AUTOSAR XML (schema 00044)
package /E40_Platform_System_SystemPackage/Components
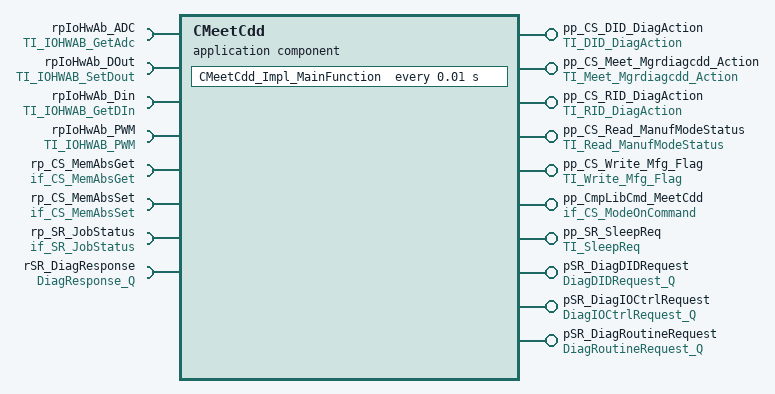
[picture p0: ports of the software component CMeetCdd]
  application sw component type CMeetCdd
    7 x provide port:
      pp_CS_DID_DiagAction: server-com-spec{operation=DID_DiagAction, queue-length=1}, provided-interface=TI_DID_DiagAction
      pp_CS_Meet_Mgrdiagcdd_Action: server-com-spec{operation=Meet_Mgrdiagcdd_Action, queue-length=1}, provided-interface=TI_Meet_Mgrdiagcdd_Action
      pp_CS_RID_DiagAction: server-com-spec{operation=RID_DiagAction, queue-length=1}, provided-interface=TI_RID_DiagAction
      pp_CS_Read_ManufModeStatus: server-com-spec{operation=Read_ManufModeStatus, queue-length=1}, provided-interface=TI_Read_ManufModeStatus
      pp_CS_Write_Mfg_Flag: server-com-spec{operation=Write_Mfg_Flag, queue-length=1}, provided-interface=TI_Write_Mfg_Flag
      pp_CmpLibCmd_MeetCdd: server-com-spec{operation=Impl_OnCommand, queue-length=1}, provided-interface=if_CS_ModeOnCommand
      pp_SR_SleepReq: nonqueued-sender-com-spec{data-element=SleepReqData, init-value=constant-reference=CMeetCddSleepReqDataValue0}, provided-interface=TI_SleepReq
    7 x require port:
      rpIoHwAb_ADC: required-com-specs=[GetAsyncRawAdc, GetProcessedAdc, GetSyncRawAdc], required-interface=TI_IOHWAB_GetAdc
      rpIoHwAb_DOut: required-com-specs=[SetOutputGroup, SetOutputPin], required-interface=TI_IOHWAB_SetDout
      rpIoHwAb_Din: required-com-specs=[GetAsyncRawInput, GetInputGroup, GetProcessedInput, GetSyncRawInput], required-interface=TI_IOHWAB_GetDIn
      rpIoHwAb_PWM: required-com-specs=[PwmSetDuty, PwmSetDutyAndPeriod, PwmSetIdeal], required-interface=TI_IOHWAB_PWM
      rp_CS_MemAbsGet: required-interface=if_CS_MemAbsGet
        required-com-specs:
          Get_BsConst_Audio_Element
          Get_BsConst_Communication_Element
          Get_BsConst_EngOffTimer_Element
          Get_BsConst_FuelGauge_Element
          Get_BsConst_OilGauge_Element
          Get_BsConst_PowerGauge_Element
          Get_BsConst_Power_Element
          Get_BsConst_RealTimeClock_Element
          Get_BsConst_ServiceReminder_Element
          Get_BsConst_SpeedoGauge_Element
          Get_BsConst_TachoGauge_Element
          Get_BsConst_TempGauge_Element
          Get_BsConst_TripComputer_Element
          Get_BsConst_Warning_Element
          Get_BsCys_Certicificate_Element
          Get_BsDiag_Dtc_Element
          Get_BsDiag_ErrorRecord_Element
          Get_BsReten_Audio_Element
          Get_BsReten_Communication_Element
          Get_BsReten_Display_Element
          Get_BsReten_Gauges_Element
          Get_BsReten_Illumination_Element
          Get_BsReten_Odometer_Element
          Get_BsReten_Personalization_Element
          Get_BsReten_Power_Element
          Get_BsReten_RealTimeClock_Element
          Get_BsReten_Tripcomputer_Element
          Get_BsReten_Warning_Element
          Get_BsRt_CusDlt_Element
          Get_BsRt_FuelGauge_Element
          Get_BsRt_Illumination_Element
          Get_BsRt_Odometer_Element
          Get_BsRt_OilGauge_Element
          Get_BsRt_Personalization_Element
          Get_BsRt_PowerGauge_Element
          Get_BsRt_RealTimeClock_Element
          Get_BsRt_SpeedoGauge_Element
          Get_BsRt_TachoGauge_Element
          Get_BsRt_TempGauge_Element
          Get_BsRt_TripComputer_Element
          Get_BsRt_Warning_Element
          Get_BsShare_EcuPartNumber_Element
          Get_BsShare_SwUpdFotaFinPrint_Element
          Get_BsShare_SwUpdFotaMode_Element
          Get_BsShare_SwUpdFotaStatus_Element
          Get_BsShare_SwUpdFotadecrypt_Element
          Get_BsShare_SwUpdReflash_Element
          Get_BsShare_VehicleConfig_Element
          Get_BsShare_VisMeet_Element
          Get_RefCys_Certicificate1_Element
          Get_RefCys_Certicificate_Element
          Get_BsShare_VisteonPartNumber
          Get_BsShare_VisteonPCBPartNumber
          Get_BsShare_SMTPlantNumber
          Get_BsShare_SMTManufacturingDate
          Get_BsShare_ProductSerialNumber
          Get_BsShare_PCBSerialNumber
          Get_BsShare_HWModification
          Get_BsShare_AssemblyPlantNumber
          Get_BsShare_AssemblyManufacturingDate
          Get_BsShare_VisMeet_EOLEntry_Element
          Get_BsConst_Temperature_Sensor_Conv_SafeCopy2
          Get_BsConst_Temperature_Sensor_Conv_SafeCopy1
          Get_BsConst_Temperature_Sensor_Conv
          Get_BsConst_Temp_Threshold_Hysteresis_Derating_SafeCopy2
          Get_BsConst_Temp_Threshold_Hysteresis_Derating_SafeCopy1
          Get_BsConst_Temp_Threshold_Hysteresis_Derating
          Get_BsConst_PWM_boost_bypass_duty_SafeCopy2
          Get_BsConst_PWM_boost_bypass_duty_SafeCopy1
          Get_BsConst_PWM_boost_bypass_duty
          Get_BsConst_PCB_Temperature_Sensor_Conv_SafeCopy2
          Get_BsConst_PCB_Temperature_Sensor_Conv_SafeCopy1
          Get_BsConst_PCB_Temperature_Sensor_Conv
          Get_BsConst_Lookup_Curve_HotSpot_Coef_Y_SafeCopy2
          Get_BsConst_Lookup_Curve_HotSpot_Coef_Y_SafeCopy1
          Get_BsConst_Lookup_Curve_HotSpot_Coef_Y
          Get_BsConst_Lookup_Curve_HotSpot_Coef_X_SafeCopy2
          Get_BsConst_Lookup_Curve_HotSpot_Coef_X_SafeCopy1
          Get_BsConst_Lookup_Curve_HotSpot_Coef_X
          Get_BsConst_Display_Illum_Max_Level_SafeCopy2
          Get_BsConst_Display_Illum_Max_Level_SafeCopy1
          Get_BsConst_Display_Illum_Max_Level
          Get_BsConst_Derating_Backlight_Disable_SafeCopy2
          Get_BsConst_Derating_Backlight_Disable_SafeCopy1
          Get_BsConst_Derating_Backlight_Disable
          Get_BsConst_Compensation_Line_Slope_m_SafeCopy2
          Get_BsConst_Compensation_Line_Slope_m_SafeCopy1
          Get_BsConst_Compensation_Line_Slope_m
          Get_BsConst_Compensation_Line_Shift_b_SafeCopy2
          Get_BsConst_Compensation_Line_Shift_b_SafeCopy1
          Get_BsConst_Compensation_Line_Shift_b
          Get_BsConst_BsConst_Illumination_ReservedByte_SafeCopy2
          Get_BsConst_BsConst_Illumination_ReservedByte_SafeCopy1
          Get_BsConst_BsConst_Illumination_ReservedByte
      rp_CS_MemAbsSet: required-interface=if_CS_MemAbsSet
        required-com-specs:
          Set_BsConst_Audio_Element
          Set_BsConst_Communication_Element
          Set_BsConst_EngOffTimer_Element
          Set_BsConst_FuelGauge_Element
          Set_BsConst_OilGauge_Element
          Set_BsConst_PowerGauge_Element
          Set_BsConst_Power_Element
          Set_BsConst_RealTimeClock_Element
          Set_BsConst_ServiceReminder_Element
          Set_BsConst_SpeedoGauge_Element
          Set_BsConst_TachoGauge_Element
          Set_BsConst_TempGauge_Element
          Set_BsConst_TripComputer_Element
          Set_BsConst_Warning_Element
          Set_BsCys_Certicificate_Element
          Set_BsDiag_Dtc_Element
          Set_BsDiag_ErrorRecord_Element
          Set_BsReten_Audio_Element
          Set_BsReten_Communication_Element
          Set_BsReten_Display_Element
          Set_BsReten_Gauges_Element
          Set_BsReten_Illumination_Element
          Set_BsReten_Odometer_Element
          Set_BsReten_Personalization_Element
          Set_BsReten_Power_Element
          Set_BsReten_RealTimeClock_Element
          Set_BsReten_Tripcomputer_Element
          Set_BsReten_Warning_Element
          Set_BsRt_CusDlt_Element
          Set_BsRt_FuelGauge_Element
          Set_BsRt_Illumination_Element
          Set_BsRt_Odometer_Element
          Set_BsRt_OilGauge_Element
          Set_BsRt_Personalization_Element
          Set_BsRt_PowerGauge_Element
          Set_BsRt_RealTimeClock_Element
          Set_BsRt_SpeedoGauge_Element
          Set_BsRt_TachoGauge_Element
          Set_BsRt_TempGauge_Element
          Set_BsRt_TripComputer_Element
          Set_BsRt_Warning_Element
          Set_BsShare_EcuPartNumber_Element
          Set_BsShare_SwUpdFotaFinPrint_Element
          Set_BsShare_SwUpdFotaMode_Element
          Set_BsShare_SwUpdFotaStatus_Element
          Set_BsShare_SwUpdFotadecrypt_Element
          Set_BsShare_SwUpdReflash_Element
          Set_BsShare_VehicleConfig_Element
          Set_BsShare_VisMeet_Element
          Set_RefCys_Certicificate1_Element
          Set_RefCys_Certicificate_Element
          Set_BsShare_VisteonPartNumber
          Set_BsShare_VisteonPCBPartNumber
          Set_BsShare_SMTPlantNumber
          Set_BsShare_SMTManufacturingDate
          Set_BsShare_ProductSerialNumber
          Set_BsShare_PCBSerialNumber
          Set_BsShare_HWModification
          Set_BsShare_AssemblyPlantNumber
          Set_BsShare_AssemblyManufacturingDate
          Set_BsShare_VisMeet_EOLEntry_Element
          Set_BsConst_Temperature_Sensor_Conv_SafeCopy2
          Set_BsConst_Temperature_Sensor_Conv_SafeCopy1
          Set_BsConst_Temperature_Sensor_Conv
          Set_BsConst_Temp_Threshold_Hysteresis_Derating_SafeCopy2
          Set_BsConst_Temp_Threshold_Hysteresis_Derating_SafeCopy1
          Set_BsConst_Temp_Threshold_Hysteresis_Derating
          Set_BsConst_PWM_boost_bypass_duty_SafeCopy2
          Set_BsConst_PWM_boost_bypass_duty_SafeCopy1
          Set_BsConst_PWM_boost_bypass_duty
          Set_BsConst_PCB_Temperature_Sensor_Conv_SafeCopy2
          Set_BsConst_PCB_Temperature_Sensor_Conv_SafeCopy1
          Set_BsConst_PCB_Temperature_Sensor_Conv
          Set_BsConst_Lookup_Curve_HotSpot_Coef_Y_SafeCopy2
          Set_BsConst_Lookup_Curve_HotSpot_Coef_Y_SafeCopy1
          Set_BsConst_Lookup_Curve_HotSpot_Coef_Y
          Set_BsConst_Lookup_Curve_HotSpot_Coef_X_SafeCopy2
          Set_BsConst_Lookup_Curve_HotSpot_Coef_X_SafeCopy1
          Set_BsConst_Lookup_Curve_HotSpot_Coef_X
          Set_BsConst_Display_Illum_Max_Level_SafeCopy2
          Set_BsConst_Display_Illum_Max_Level_SafeCopy1
          Set_BsConst_Display_Illum_Max_Level
          Set_BsConst_Derating_Backlight_Disable_SafeCopy2
          Set_BsConst_Derating_Backlight_Disable_SafeCopy1
          Set_BsConst_Derating_Backlight_Disable
          Set_BsConst_Compensation_Line_Slope_m_SafeCopy2
          Set_BsConst_Compensation_Line_Slope_m_SafeCopy1
          Set_BsConst_Compensation_Line_Slope_m
          Set_BsConst_Compensation_Line_Shift_b_SafeCopy2
          Set_BsConst_Compensation_Line_Shift_b_SafeCopy1
          Set_BsConst_Compensation_Line_Shift_b
          Set_BsConst_BsConst_Illumination_ReservedByte_SafeCopy2
          Set_BsConst_BsConst_Illumination_ReservedByte_SafeCopy1
          Set_BsConst_BsConst_Illumination_ReservedByte
      rp_SR_JobStatus: required-interface=if_SR_JobStatus
        required-com-specs:
          data-element=JobStatus_BsConst_Audio_Element, init-value=constant-reference=CMeetCddJobStatus_BsConst_Audio_ElementValue0
          data-element=JobStatus_BsConst_Communication_Element, init-value=constant-reference=CMeetCddJobStatus_BsConst_Communication_ElementValue0
          data-element=JobStatus_BsConst_EngOffTimer_Element, init-value=constant-reference=CMeetCddJobStatus_BsConst_EngOffTimer_ElementValue0
          data-element=JobStatus_BsConst_FuelGauge_Element, init-value=constant-reference=CMeetCddJobStatus_BsConst_FuelGauge_ElementValue0
          data-element=JobStatus_BsConst_OilGauge_Element, init-value=constant-reference=CMeetCddJobStatus_BsConst_OilGauge_ElementValue0
          data-element=JobStatus_BsConst_PowerGauge_Element, init-value=constant-reference=CMeetCddJobStatus_BsConst_PowerGauge_ElementValue0
          data-element=JobStatus_BsConst_Power_Element, init-value=constant-reference=CMeetCddJobStatus_BsConst_Power_ElementValue0
          data-element=JobStatus_BsConst_RealTimeClock_Element, init-value=constant-reference=CMeetCddJobStatus_BsConst_RealTimeClock_ElementValue0
          data-element=JobStatus_BsConst_ServiceReminder_Element, init-value=constant-reference=CMeetCddJobStatus_BsConst_ServiceReminder_ElementValue0
          data-element=JobStatus_BsConst_SpeedoGauge_Element, init-value=constant-reference=CMeetCddJobStatus_BsConst_SpeedoGauge_ElementValue0
          data-element=JobStatus_BsConst_TachoGauge_Element, init-value=constant-reference=CMeetCddJobStatus_BsConst_TachoGauge_ElementValue0
          data-element=JobStatus_BsConst_TempGauge_Element, init-value=constant-reference=CMeetCddJobStatus_BsConst_TempGauge_ElementValue0
          data-element=JobStatus_BsConst_TripComputer_Element, init-value=constant-reference=CMeetCddJobStatus_BsConst_TripComputer_ElementValue0
          data-element=JobStatus_BsConst_Warning_Element, init-value=constant-reference=CMeetCddJobStatus_BsConst_Warning_ElementValue0
          data-element=JobStatus_BsCys_Certicificate_Element, init-value=constant-reference=CMeetCddJobStatus_BsCys_Certicificate_ElementValue0
          data-element=JobStatus_BsDiag_Dtc_Element, init-value=constant-reference=CMeetCddJobStatus_BsDiag_Dtc_ElementValue0
          data-element=JobStatus_BsDiag_ErrorRecord_Element, init-value=constant-reference=CMeetCddJobStatus_BsDiag_ErrorRecord_ElementValue0
          data-element=JobStatus_BsReten_Audio_Element, init-value=constant-reference=CMeetCddJobStatus_BsReten_Audio_ElementValue0
          data-element=JobStatus_BsReten_Communication_Element, init-value=constant-reference=CMeetCddJobStatus_BsReten_Communication_ElementValue0
          data-element=JobStatus_BsReten_Display_Element, init-value=constant-reference=CMeetCddJobStatus_BsReten_Display_ElementValue0
          data-element=JobStatus_BsReten_Gauges_Element, init-value=constant-reference=CMeetCddJobStatus_BsReten_Gauges_ElementValue0
          data-element=JobStatus_BsReten_Illumination_Element, init-value=constant-reference=CMeetCddJobStatus_BsReten_Illumination_ElementValue0
          data-element=JobStatus_BsReten_Odometer_Element, init-value=constant-reference=CMeetCddJobStatus_BsReten_Odometer_ElementValue0
          data-element=JobStatus_BsReten_Personalization_Element, init-value=constant-reference=CMeetCddJobStatus_BsReten_Personalization_ElementValue0
          data-element=JobStatus_BsReten_Power_Element, init-value=constant-reference=CMeetCddJobStatus_BsReten_Power_ElementValue0
          data-element=JobStatus_BsReten_RealTimeClock_Element, init-value=constant-reference=CMeetCddJobStatus_BsReten_RealTimeClock_ElementValue0
          data-element=JobStatus_BsReten_Tripcomputer_Element, init-value=constant-reference=CMeetCddJobStatus_BsReten_Tripcomputer_ElementValue0
          data-element=JobStatus_BsReten_Warning_Element, init-value=constant-reference=CMeetCddJobStatus_BsReten_Warning_ElementValue0
          data-element=JobStatus_BsRt_CusDlt_Element, init-value=constant-reference=CMeetCddJobStatus_BsRt_CusDlt_ElementValue0
          data-element=JobStatus_BsRt_FuelGauge_Element, init-value=constant-reference=CMeetCddJobStatus_BsRt_FuelGauge_ElementValue0
          data-element=JobStatus_BsRt_Illumination_Element, init-value=constant-reference=CMeetCddJobStatus_BsRt_Illumination_ElementValue0
          data-element=JobStatus_BsRt_Odometer_Element, init-value=constant-reference=CMeetCddJobStatus_BsRt_Odometer_ElementValue0
          data-element=JobStatus_BsRt_OilGauge_Element, init-value=constant-reference=CMeetCddJobStatus_BsRt_OilGauge_ElementValue0
          data-element=JobStatus_BsRt_Personalization_Element, init-value=constant-reference=CMeetCddJobStatus_BsRt_Personalization_ElementValue0
          data-element=JobStatus_BsRt_PowerGauge_Element, init-value=constant-reference=CMeetCddJobStatus_BsRt_PowerGauge_ElementValue0
          data-element=JobStatus_BsRt_RealTimeClock_Element, init-value=constant-reference=CMeetCddJobStatus_BsRt_RealTimeClock_ElementValue0
          data-element=JobStatus_BsRt_SpeedoGauge_Element, init-value=constant-reference=CMeetCddJobStatus_BsRt_SpeedoGauge_ElementValue0
          data-element=JobStatus_BsRt_TachoGauge_Element, init-value=constant-reference=CMeetCddJobStatus_BsRt_TachoGauge_ElementValue0
          data-element=JobStatus_BsRt_TempGauge_Element, init-value=constant-reference=CMeetCddJobStatus_BsRt_TempGauge_ElementValue0
          data-element=JobStatus_BsRt_TripComputer_Element, init-value=constant-reference=CMeetCddJobStatus_BsRt_TripComputer_ElementValue0
          data-element=JobStatus_BsRt_Warning_Element, init-value=constant-reference=CMeetCddJobStatus_BsRt_Warning_ElementValue0
          data-element=JobStatus_BsShare_EcuPartNumber_Element, init-value=constant-reference=CMeetCddJobStatus_BsShare_EcuPartNumber_ElementValue0
          data-element=JobStatus_BsShare_SwUpdFotaFinPrint_Element, init-value=constant-reference=CMeetCddJobStatus_BsShare_SwUpdFotaFinPrint_ElementValue0
          data-element=JobStatus_BsShare_SwUpdFotaMode_Element, init-value=constant-reference=CMeetCddJobStatus_BsShare_SwUpdFotaMode_ElementValue0
          data-element=JobStatus_BsShare_SwUpdFotaStatus_Element, init-value=constant-reference=CMeetCddJobStatus_BsShare_SwUpdFotaStatus_ElementValue0
          data-element=JobStatus_BsShare_SwUpdFotadecrypt_Element, init-value=constant-reference=CMeetCddJobStatus_BsShare_SwUpdFotadecrypt_ElementValue0
          data-element=JobStatus_BsShare_SwUpdReflash_Element, init-value=constant-reference=CMeetCddJobStatus_BsShare_SwUpdReflash_ElementValue0
          data-element=JobStatus_BsShare_VehicleConfig_Element, init-value=constant-reference=CMeetCddJobStatus_BsShare_VehicleConfig_ElementValue0
          data-element=JobStatus_BsShare_VisMeet_Element, init-value=constant-reference=CMeetCddJobStatus_BsShare_VisMeet_ElementValue0
          data-element=JobStatus_RefCys_Certicificate1_Element, init-value=constant-reference=CMeetCddJobStatus_RefCys_Certicificate1_ElementValue0
          data-element=JobStatus_RefCys_Certicificate_Element, init-value=constant-reference=CMeetCddJobStatus_RefCys_Certicificate_ElementValue0
          data-element=JobStatus_BsShare_VisMeet_EOLEntry_Element, init-value=constant-reference=CMeetCddJobStatus_BsShare_VisMeet_EOLEntry_ElementValue0
          data-element=JobStatus_BsShare_AssemblyManufacturingDate, init-value=constant-reference=CMeetCddJobStatus_BsShare_AssemblyManufacturingDateValue0
          data-element=JobStatus_BsShare_AssemblyPlantNumber, init-value=constant-reference=CMeetCddJobStatus_BsShare_AssemblyPlantNumberValue0
          data-element=JobStatus_BsShare_HWModification, init-value=constant-reference=CMeetCddJobStatus_BsShare_HWModificationValue0
          data-element=JobStatus_BsShare_PCBSerialNumber, init-value=constant-reference=CMeetCddJobStatus_BsShare_PCBSerialNumberValue0
          data-element=JobStatus_BsShare_ProductSerialNumber, init-value=constant-reference=CMeetCddJobStatus_BsShare_ProductSerialNumberValue0
          data-element=JobStatus_BsShare_SMTManufacturingDate, init-value=constant-reference=CMeetCddJobStatus_BsShare_SMTManufacturingDateValue0
          data-element=JobStatus_BsShare_SMTPlantNumber, init-value=constant-reference=CMeetCddJobStatus_BsShare_SMTPlantNumberValue0
          data-element=JobStatus_BsShare_VisteonPCBPartNumber, init-value=constant-reference=CMeetCddJobStatus_BsShare_VisteonPCBPartNumberValue0
          data-element=JobStatus_BsShare_VisteonPartNumber, init-value=constant-reference=CMeetCddJobStatus_BsShare_VisteonPartNumberValue0
          data-element=JobStatus_BsConst_BsConst_Illumination_ReservedByte, init-value=constant-reference=CMeetCddJobStatus_BsConst_BsConst_Illumination_ReservedByteValue0
          data-element=JobStatus_BsConst_BsConst_Illumination_ReservedByte_SafeCopy1, init-value=constant-reference=CMeetCddJobStatus_BsConst_BsConst_Illumination_ReservedByte_SafeCopy1Value0
          data-element=JobStatus_BsConst_BsConst_Illumination_ReservedByte_SafeCopy2, init-value=constant-reference=CMeetCddJobStatus_BsConst_BsConst_Illumination_ReservedByte_SafeCopy2Value0
          data-element=JobStatus_BsConst_Compensation_Line_Shift_b, init-value=constant-reference=CMeetCddJobStatus_BsConst_Compensation_Line_Shift_bValue0
          data-element=JobStatus_BsConst_Compensation_Line_Shift_b_SafeCopy1, init-value=constant-reference=CMeetCddJobStatus_BsConst_Compensation_Line_Shift_b_SafeCopy1Value0
          data-element=JobStatus_BsConst_Compensation_Line_Shift_b_SafeCopy2, init-value=constant-reference=CMeetCddJobStatus_BsConst_Compensation_Line_Shift_b_SafeCopy2Value0
          data-element=JobStatus_BsConst_Compensation_Line_Slope_m, init-value=constant-reference=CMeetCddJobStatus_BsConst_Compensation_Line_Slope_mValue0
          data-element=JobStatus_BsConst_Compensation_Line_Slope_m_SafeCopy1, init-value=constant-reference=CMeetCddJobStatus_BsConst_Compensation_Line_Slope_m_SafeCopy1Value0
          data-element=JobStatus_BsConst_Compensation_Line_Slope_m_SafeCopy2, init-value=constant-reference=CMeetCddJobStatus_BsConst_Compensation_Line_Slope_m_SafeCopy2Value0
          data-element=JobStatus_BsConst_Derating_Backlight_Disable, init-value=constant-reference=CMeetCddJobStatus_BsConst_Derating_Backlight_DisableValue0
          data-element=JobStatus_BsConst_Derating_Backlight_Disable_SafeCopy1, init-value=constant-reference=CMeetCddJobStatus_BsConst_Derating_Backlight_Disable_SafeCopy1Value0
          data-element=JobStatus_BsConst_Derating_Backlight_Disable_SafeCopy2, init-value=constant-reference=CMeetCddJobStatus_BsConst_Derating_Backlight_Disable_SafeCopy2Value0
          data-element=JobStatus_BsConst_Display_Illum_Max_Level, init-value=constant-reference=CMeetCddJobStatus_BsConst_Display_Illum_Max_LevelValue0
          data-element=JobStatus_BsConst_Display_Illum_Max_Level_SafeCopy1, init-value=constant-reference=CMeetCddJobStatus_BsConst_Display_Illum_Max_Level_SafeCopy1Value0
          data-element=JobStatus_BsConst_Display_Illum_Max_Level_SafeCopy2, init-value=constant-reference=CMeetCddJobStatus_BsConst_Display_Illum_Max_Level_SafeCopy2Value0
          data-element=JobStatus_BsConst_Lookup_Curve_HotSpot_Coef_X, init-value=constant-reference=CMeetCddJobStatus_BsConst_Lookup_Curve_HotSpot_Coef_XValue0
          data-element=JobStatus_BsConst_Lookup_Curve_HotSpot_Coef_X_SafeCopy1, init-value=constant-reference=CMeetCddJobStatus_BsConst_Lookup_Curve_HotSpot_Coef_X_SafeCopy1Value0
          data-element=JobStatus_BsConst_Lookup_Curve_HotSpot_Coef_X_SafeCopy2, init-value=constant-reference=CMeetCddJobStatus_BsConst_Lookup_Curve_HotSpot_Coef_X_SafeCopy2Value0
          data-element=JobStatus_BsConst_Lookup_Curve_HotSpot_Coef_Y, init-value=constant-reference=CMeetCddJobStatus_BsConst_Lookup_Curve_HotSpot_Coef_YValue0
          data-element=JobStatus_BsConst_Lookup_Curve_HotSpot_Coef_Y_SafeCopy1, init-value=constant-reference=CMeetCddJobStatus_BsConst_Lookup_Curve_HotSpot_Coef_Y_SafeCopy1Value0
          data-element=JobStatus_BsConst_Lookup_Curve_HotSpot_Coef_Y_SafeCopy2, init-value=constant-reference=CMeetCddJobStatus_BsConst_Lookup_Curve_HotSpot_Coef_Y_SafeCopy2Value0
          data-element=JobStatus_BsConst_PCB_Temperature_Sensor_Conv, init-value=constant-reference=CMeetCddJobStatus_BsConst_PCB_Temperature_Sensor_ConvValue0
          data-element=JobStatus_BsConst_PCB_Temperature_Sensor_Conv_SafeCopy1, init-value=constant-reference=CMeetCddJobStatus_BsConst_PCB_Temperature_Sensor_Conv_SafeCopy1Value0
          data-element=JobStatus_BsConst_PCB_Temperature_Sensor_Conv_SafeCopy2, init-value=constant-reference=CMeetCddJobStatus_BsConst_PCB_Temperature_Sensor_Conv_SafeCopy2Value0
          data-element=JobStatus_BsConst_PWM_boost_bypass_duty, init-value=constant-reference=CMeetCddJobStatus_BsConst_PWM_boost_bypass_dutyValue0
          data-element=JobStatus_BsConst_PWM_boost_bypass_duty_SafeCopy1, init-value=constant-reference=CMeetCddJobStatus_BsConst_PWM_boost_bypass_duty_SafeCopy1Value0
          data-element=JobStatus_BsConst_PWM_boost_bypass_duty_SafeCopy2, init-value=constant-reference=CMeetCddJobStatus_BsConst_PWM_boost_bypass_duty_SafeCopy2Value0
          data-element=JobStatus_BsConst_Temp_Threshold_Hysteresis_Derating, init-value=constant-reference=CMeetCddJobStatus_BsConst_Temp_Threshold_Hysteresis_DeratingValue0
          data-element=JobStatus_BsConst_Temp_Threshold_Hysteresis_Derating_SafeCopy1, init-value=constant-reference=CMeetCddJobStatus_BsConst_Temp_Threshold_Hysteresis_Derating_SafeCopy1Value0
          data-element=JobStatus_BsConst_Temp_Threshold_Hysteresis_Derating_SafeCopy2, init-value=constant-reference=CMeetCddJobStatus_BsConst_Temp_Threshold_Hysteresis_Derating_SafeCopy2Value0
          data-element=JobStatus_BsConst_Temperature_Sensor_Conv, init-value=constant-reference=CMeetCddJobStatus_BsConst_Temperature_Sensor_ConvValue0
          data-element=JobStatus_BsConst_Temperature_Sensor_Conv_SafeCopy1, init-value=constant-reference=CMeetCddJobStatus_BsConst_Temperature_Sensor_Conv_SafeCopy1Value0
          data-element=JobStatus_BsConst_Temperature_Sensor_Conv_SafeCopy2, init-value=constant-reference=CMeetCddJobStatus_BsConst_Temperature_Sensor_Conv_SafeCopy2Value0
    provide port pSR_DiagDIDRequest: queued-sender-com-spec=DiagDIDRequestData, provided-interface=DiagDIDRequest_Q
    provide port pSR_DiagIOCtrlRequest: queued-sender-com-spec=DiagIOCtrlRequestData, provided-interface=DiagIOCtrlRequest_Q
    provide port pSR_DiagRoutineRequest: queued-sender-com-spec=DiagRoutineRequestData, provided-interface=DiagRoutineRequest_Q
    require port rSR_DiagResponse: queued-receiver-com-spec{data-element=DiagResponseData, queue-length=2}, required-interface=DiagResponse_Q
    behavior IB_CMeetCdd
      operation invoked event OIE_pp_CS_DID_DiagAction_CMeetCdd_DID_DiagActionTrigByDID_DiagAction: start-on-event=CMeetCdd_DID_DiagAction, operation=pp_CS_DID_DiagAction.DID_DiagAction
      timing event TECMeetCdd_Impl_MainFunction: start-on-event=CMeetCdd_Impl_MainFunction, period=0.01
      5 x operation invoked event:
        OIE_pp_CmpLibCmd_MeetCdd_CMeetCdd_Impl_OnCommandTrigByImpl_OnCommand: start-on-event=CMeetCdd_Impl_OnCommand, operation=pp_CmpLibCmd_MeetCdd.Impl_OnCommand
        OIE_pp_CS_Meet_Mgrdiagcdd_Action_CMeetCdd_Meet_Mgrdiagcdd_ActionTrigByMeet_Mgrdiagcdd_Action: start-on-event=CMeetCdd_Meet_Mgrdiagcdd_Action, operation=pp_CS_Meet_Mgrdiagcdd_Action.Meet_Mgrdiagcdd_Action
        OIE_pp_CS_RID_DiagAction_CMeetCdd_RID_DiagActionTrigByRID_DiagAction: start-on-event=CMeetCdd_RID_DiagAction, operation=pp_CS_RID_DiagAction.RID_DiagAction
        OIE_pp_CS_Read_ManufModeStatus_CMeetCdd_Read_ManufModeStatusTrigByRead_ManufModeStatus: start-on-event=CMeetCdd_Read_ManufModeStatus, operation=pp_CS_Read_ManufModeStatus.Read_ManufModeStatus
        OIE_pp_CS_Write_Mfg_Flag_CMeetCdd_Write_Mfg_FlagTrigByWrite_Mfg_Flag: start-on-event=CMeetCdd_Write_Mfg_Flag, operation=pp_CS_Write_Mfg_Flag.Write_Mfg_Flag
      port-api-options:
        enable-take-address=false, indirect-api=false, port=pp_CS_DID_DiagAction
        enable-take-address=false, indirect-api=false, port=pp_CS_Meet_Mgrdiagcdd_Action
        enable-take-address=false, indirect-api=false, port=pp_CS_RID_DiagAction
        enable-take-address=false, indirect-api=false, port=pp_CS_Read_ManufModeStatus
        enable-take-address=false, indirect-api=false, port=pp_CS_Write_Mfg_Flag
        enable-take-address=false, indirect-api=false, port=pp_CmpLibCmd_MeetCdd
        enable-take-address=false, indirect-api=false, port=pp_SR_SleepReq
        enable-take-address=false, indirect-api=false, port=rpIoHwAb_ADC
        enable-take-address=false, indirect-api=false, port=rpIoHwAb_DOut
        enable-take-address=false, indirect-api=false, port=rpIoHwAb_Din
        enable-take-address=false, indirect-api=false, port=rpIoHwAb_PWM
        enable-take-address=false, indirect-api=false, port=rp_CS_MemAbsGet
        enable-take-address=false, indirect-api=false, port=rp_CS_MemAbsSet
        enable-take-address=false, indirect-api=false, port=rp_SR_JobStatus
        enable-take-address=false, indirect-api=false, port=pSR_DiagDIDRequest
        enable-take-address=false, indirect-api=false, port=pSR_DiagIOCtrlRequest
        enable-take-address=false, indirect-api=false, port=pSR_DiagRoutineRequest
        enable-take-address=false, indirect-api=false, port=rSR_DiagResponse
      7 x runnable, all with can-be-invoked-concurrently=true:
        CMeetCdd_DID_DiagAction
        CMeetCdd_Impl_MainFunction
          data-receive-point-by-arguments:
            95 x access:
              DRA_rp_SR_JobStatus_JobStatus_BsConst_Audio_Element: accessed-variable=rp_SR_JobStatus.JobStatus_BsConst_Audio_Element
              DRA_rp_SR_JobStatus_JobStatus_BsConst_Communication_Element: accessed-variable=rp_SR_JobStatus.JobStatus_BsConst_Communication_Element
              DRA_rp_SR_JobStatus_JobStatus_BsConst_EngOffTimer_Element: accessed-variable=rp_SR_JobStatus.JobStatus_BsConst_EngOffTimer_Element
              DRA_rp_SR_JobStatus_JobStatus_BsConst_FuelGauge_Element: accessed-variable=rp_SR_JobStatus.JobStatus_BsConst_FuelGauge_Element
              DRA_rp_SR_JobStatus_JobStatus_BsConst_OilGauge_Element: accessed-variable=rp_SR_JobStatus.JobStatus_BsConst_OilGauge_Element
              DRA_rp_SR_JobStatus_JobStatus_BsConst_PowerGauge_Element: accessed-variable=rp_SR_JobStatus.JobStatus_BsConst_PowerGauge_Element
              DRA_rp_SR_JobStatus_JobStatus_BsConst_Power_Element: accessed-variable=rp_SR_JobStatus.JobStatus_BsConst_Power_Element
              DRA_rp_SR_JobStatus_JobStatus_BsConst_RealTimeClock_Element: accessed-variable=rp_SR_JobStatus.JobStatus_BsConst_RealTimeClock_Element
              DRA_rp_SR_JobStatus_JobStatus_BsConst_ServiceReminder_Element: accessed-variable=rp_SR_JobStatus.JobStatus_BsConst_ServiceReminder_Element
              DRA_rp_SR_JobStatus_JobStatus_BsConst_SpeedoGauge_Element: accessed-variable=rp_SR_JobStatus.JobStatus_BsConst_SpeedoGauge_Element
              DRA_rp_SR_JobStatus_JobStatus_BsConst_TachoGauge_Element: accessed-variable=rp_SR_JobStatus.JobStatus_BsConst_TachoGauge_Element
              DRA_rp_SR_JobStatus_JobStatus_BsConst_TempGauge_Element: accessed-variable=rp_SR_JobStatus.JobStatus_BsConst_TempGauge_Element
              DRA_rp_SR_JobStatus_JobStatus_BsConst_TripComputer_Element: accessed-variable=rp_SR_JobStatus.JobStatus_BsConst_TripComputer_Element
              DRA_rp_SR_JobStatus_JobStatus_BsConst_Warning_Element: accessed-variable=rp_SR_JobStatus.JobStatus_BsConst_Warning_Element
              DRA_rp_SR_JobStatus_JobStatus_BsCys_Certicificate_Element: accessed-variable=rp_SR_JobStatus.JobStatus_BsCys_Certicificate_Element
              DRA_rp_SR_JobStatus_JobStatus_BsDiag_Dtc_Element: accessed-variable=rp_SR_JobStatus.JobStatus_BsDiag_Dtc_Element
              DRA_rp_SR_JobStatus_JobStatus_BsDiag_ErrorRecord_Element: accessed-variable=rp_SR_JobStatus.JobStatus_BsDiag_ErrorRecord_Element
              DRA_rp_SR_JobStatus_JobStatus_BsReten_Audio_Element: accessed-variable=rp_SR_JobStatus.JobStatus_BsReten_Audio_Element
              DRA_rp_SR_JobStatus_JobStatus_BsReten_Communication_Element: accessed-variable=rp_SR_JobStatus.JobStatus_BsReten_Communication_Element
              DRA_rp_SR_JobStatus_JobStatus_BsReten_Display_Element: accessed-variable=rp_SR_JobStatus.JobStatus_BsReten_Display_Element
              DRA_rp_SR_JobStatus_JobStatus_BsReten_Gauges_Element: accessed-variable=rp_SR_JobStatus.JobStatus_BsReten_Gauges_Element
              DRA_rp_SR_JobStatus_JobStatus_BsReten_Illumination_Element: accessed-variable=rp_SR_JobStatus.JobStatus_BsReten_Illumination_Element
              DRA_rp_SR_JobStatus_JobStatus_BsReten_Odometer_Element: accessed-variable=rp_SR_JobStatus.JobStatus_BsReten_Odometer_Element
              DRA_rp_SR_JobStatus_JobStatus_BsReten_Personalization_Element: accessed-variable=rp_SR_JobStatus.JobStatus_BsReten_Personalization_Element
              DRA_rp_SR_JobStatus_JobStatus_BsReten_Power_Element: accessed-variable=rp_SR_JobStatus.JobStatus_BsReten_Power_Element
              DRA_rp_SR_JobStatus_JobStatus_BsReten_RealTimeClock_Element: accessed-variable=rp_SR_JobStatus.JobStatus_BsReten_RealTimeClock_Element
              DRA_rp_SR_JobStatus_JobStatus_BsReten_Tripcomputer_Element: accessed-variable=rp_SR_JobStatus.JobStatus_BsReten_Tripcomputer_Element
              DRA_rp_SR_JobStatus_JobStatus_BsReten_Warning_Element: accessed-variable=rp_SR_JobStatus.JobStatus_BsReten_Warning_Element
              DRA_rp_SR_JobStatus_JobStatus_BsRt_CusDlt_Element: accessed-variable=rp_SR_JobStatus.JobStatus_BsRt_CusDlt_Element
              DRA_rp_SR_JobStatus_JobStatus_BsRt_FuelGauge_Element: accessed-variable=rp_SR_JobStatus.JobStatus_BsRt_FuelGauge_Element
              DRA_rp_SR_JobStatus_JobStatus_BsRt_Illumination_Element: accessed-variable=rp_SR_JobStatus.JobStatus_BsRt_Illumination_Element
              DRA_rp_SR_JobStatus_JobStatus_BsRt_Odometer_Element: accessed-variable=rp_SR_JobStatus.JobStatus_BsRt_Odometer_Element
              DRA_rp_SR_JobStatus_JobStatus_BsRt_OilGauge_Element: accessed-variable=rp_SR_JobStatus.JobStatus_BsRt_OilGauge_Element
              DRA_rp_SR_JobStatus_JobStatus_BsRt_Personalization_Element: accessed-variable=rp_SR_JobStatus.JobStatus_BsRt_Personalization_Element
              DRA_rp_SR_JobStatus_JobStatus_BsRt_PowerGauge_Element: accessed-variable=rp_SR_JobStatus.JobStatus_BsRt_PowerGauge_Element
              DRA_rp_SR_JobStatus_JobStatus_BsRt_RealTimeClock_Element: accessed-variable=rp_SR_JobStatus.JobStatus_BsRt_RealTimeClock_Element
              DRA_rp_SR_JobStatus_JobStatus_BsRt_SpeedoGauge_Element: accessed-variable=rp_SR_JobStatus.JobStatus_BsRt_SpeedoGauge_Element
              DRA_rp_SR_JobStatus_JobStatus_BsRt_TachoGauge_Element: accessed-variable=rp_SR_JobStatus.JobStatus_BsRt_TachoGauge_Element
              DRA_rp_SR_JobStatus_JobStatus_BsRt_TempGauge_Element: accessed-variable=rp_SR_JobStatus.JobStatus_BsRt_TempGauge_Element
              DRA_rp_SR_JobStatus_JobStatus_BsRt_TripComputer_Element: accessed-variable=rp_SR_JobStatus.JobStatus_BsRt_TripComputer_Element
              DRA_rp_SR_JobStatus_JobStatus_BsRt_Warning_Element: accessed-variable=rp_SR_JobStatus.JobStatus_BsRt_Warning_Element
              DRA_rp_SR_JobStatus_JobStatus_BsShare_EcuPartNumber_Element: accessed-variable=rp_SR_JobStatus.JobStatus_BsShare_EcuPartNumber_Element
              DRA_rp_SR_JobStatus_JobStatus_BsShare_SwUpdFotaFinPrint_Element: accessed-variable=rp_SR_JobStatus.JobStatus_BsShare_SwUpdFotaFinPrint_Element
              DRA_rp_SR_JobStatus_JobStatus_BsShare_SwUpdFotaMode_Element: accessed-variable=rp_SR_JobStatus.JobStatus_BsShare_SwUpdFotaMode_Element
              DRA_rp_SR_JobStatus_JobStatus_BsShare_SwUpdFotaStatus_Element: accessed-variable=rp_SR_JobStatus.JobStatus_BsShare_SwUpdFotaStatus_Element
              DRA_rp_SR_JobStatus_JobStatus_BsShare_SwUpdFotadecrypt_Element: accessed-variable=rp_SR_JobStatus.JobStatus_BsShare_SwUpdFotadecrypt_Element
              DRA_rp_SR_JobStatus_JobStatus_BsShare_SwUpdReflash_Element: accessed-variable=rp_SR_JobStatus.JobStatus_BsShare_SwUpdReflash_Element
              DRA_rp_SR_JobStatus_JobStatus_BsShare_VehicleConfig_Element: accessed-variable=rp_SR_JobStatus.JobStatus_BsShare_VehicleConfig_Element
              DRA_rp_SR_JobStatus_JobStatus_BsShare_VisMeet_Element: accessed-variable=rp_SR_JobStatus.JobStatus_BsShare_VisMeet_Element
              DRA_rp_SR_JobStatus_JobStatus_RefCys_Certicificate1_Element: accessed-variable=rp_SR_JobStatus.JobStatus_RefCys_Certicificate1_Element
              DRA_rp_SR_JobStatus_JobStatus_RefCys_Certicificate_Element: accessed-variable=rp_SR_JobStatus.JobStatus_RefCys_Certicificate_Element
              DRA_rp_SR_JobStatus_JobStatus_BsShare_VisMeet_EOLEntry_Element: accessed-variable=rp_SR_JobStatus.JobStatus_BsShare_VisMeet_EOLEntry_Element
              DRA_rp_SR_JobStatus_JobStatus_BsShare_AssemblyManufacturingDate: accessed-variable=rp_SR_JobStatus.JobStatus_BsShare_AssemblyManufacturingDate
              DRA_rp_SR_JobStatus_JobStatus_BsShare_AssemblyPlantNumber: accessed-variable=rp_SR_JobStatus.JobStatus_BsShare_AssemblyPlantNumber
              DRA_rp_SR_JobStatus_JobStatus_BsShare_HWModification: accessed-variable=rp_SR_JobStatus.JobStatus_BsShare_HWModification
              DRA_rp_SR_JobStatus_JobStatus_BsShare_PCBSerialNumber: accessed-variable=rp_SR_JobStatus.JobStatus_BsShare_PCBSerialNumber
              DRA_rp_SR_JobStatus_JobStatus_BsShare_ProductSerialNumber: accessed-variable=rp_SR_JobStatus.JobStatus_BsShare_ProductSerialNumber
              DRA_rp_SR_JobStatus_JobStatus_BsShare_SMTManufacturingDate: accessed-variable=rp_SR_JobStatus.JobStatus_BsShare_SMTManufacturingDate
              DRA_rp_SR_JobStatus_JobStatus_BsShare_SMTPlantNumber: accessed-variable=rp_SR_JobStatus.JobStatus_BsShare_SMTPlantNumber
              DRA_rp_SR_JobStatus_JobStatus_BsShare_VisteonPCBPartNumber: accessed-variable=rp_SR_JobStatus.JobStatus_BsShare_VisteonPCBPartNumber
              DRA_rp_SR_JobStatus_JobStatus_BsShare_VisteonPartNumber: accessed-variable=rp_SR_JobStatus.JobStatus_BsShare_VisteonPartNumber
              DRA_rp_SR_JobStatus_JobStatus_BsConst_BsConst_Illumination_ReservedByte: accessed-variable=rp_SR_JobStatus.JobStatus_BsConst_BsConst_Illumination_ReservedByte
              DRA_rp_SR_JobStatus_JobStatus_BsConst_BsConst_Illumination_ReservedByte_SafeCopy1: accessed-variable=rp_SR_JobStatus.JobStatus_BsConst_BsConst_Illumination_ReservedByte_SafeCopy1
              DRA_rp_SR_JobStatus_JobStatus_BsConst_BsConst_Illumination_ReservedByte_SafeCopy2: accessed-variable=rp_SR_JobStatus.JobStatus_BsConst_BsConst_Illumination_ReservedByte_SafeCopy2
              DRA_rp_SR_JobStatus_JobStatus_BsConst_Compensation_Line_Shift_b: accessed-variable=rp_SR_JobStatus.JobStatus_BsConst_Compensation_Line_Shift_b
              DRA_rp_SR_JobStatus_JobStatus_BsConst_Compensation_Line_Shift_b_SafeCopy1: accessed-variable=rp_SR_JobStatus.JobStatus_BsConst_Compensation_Line_Shift_b_SafeCopy1
              DRA_rp_SR_JobStatus_JobStatus_BsConst_Compensation_Line_Shift_b_SafeCopy2: accessed-variable=rp_SR_JobStatus.JobStatus_BsConst_Compensation_Line_Shift_b_SafeCopy2
              DRA_rp_SR_JobStatus_JobStatus_BsConst_Compensation_Line_Slope_m: accessed-variable=rp_SR_JobStatus.JobStatus_BsConst_Compensation_Line_Slope_m
              DRA_rp_SR_JobStatus_JobStatus_BsConst_Compensation_Line_Slope_m_SafeCopy1: accessed-variable=rp_SR_JobStatus.JobStatus_BsConst_Compensation_Line_Slope_m_SafeCopy1
              DRA_rp_SR_JobStatus_JobStatus_BsConst_Compensation_Line_Slope_m_SafeCopy2: accessed-variable=rp_SR_JobStatus.JobStatus_BsConst_Compensation_Line_Slope_m_SafeCopy2
              DRA_rp_SR_JobStatus_JobStatus_BsConst_Derating_Backlight_Disable: accessed-variable=rp_SR_JobStatus.JobStatus_BsConst_Derating_Backlight_Disable
              DRA_rp_SR_JobStatus_JobStatus_BsConst_Derating_Backlight_Disable_SafeCopy1: accessed-variable=rp_SR_JobStatus.JobStatus_BsConst_Derating_Backlight_Disable_SafeCopy1
              DRA_rp_SR_JobStatus_JobStatus_BsConst_Derating_Backlight_Disable_SafeCopy2: accessed-variable=rp_SR_JobStatus.JobStatus_BsConst_Derating_Backlight_Disable_SafeCopy2
              DRA_rp_SR_JobStatus_JobStatus_BsConst_Display_Illum_Max_Level: accessed-variable=rp_SR_JobStatus.JobStatus_BsConst_Display_Illum_Max_Level
              DRA_rp_SR_JobStatus_JobStatus_BsConst_Display_Illum_Max_Level_SafeCopy1: accessed-variable=rp_SR_JobStatus.JobStatus_BsConst_Display_Illum_Max_Level_SafeCopy1
              DRA_rp_SR_JobStatus_JobStatus_BsConst_Display_Illum_Max_Level_SafeCopy2: accessed-variable=rp_SR_JobStatus.JobStatus_BsConst_Display_Illum_Max_Level_SafeCopy2
              DRA_rp_SR_JobStatus_JobStatus_BsConst_Lookup_Curve_HotSpot_Coef_X: accessed-variable=rp_SR_JobStatus.JobStatus_BsConst_Lookup_Curve_HotSpot_Coef_X
              DRA_rp_SR_JobStatus_JobStatus_BsConst_Lookup_Curve_HotSpot_Coef_X_SafeCopy1: accessed-variable=rp_SR_JobStatus.JobStatus_BsConst_Lookup_Curve_HotSpot_Coef_X_SafeCopy1
              DRA_rp_SR_JobStatus_JobStatus_BsConst_Lookup_Curve_HotSpot_Coef_X_SafeCopy2: accessed-variable=rp_SR_JobStatus.JobStatus_BsConst_Lookup_Curve_HotSpot_Coef_X_SafeCopy2
              DRA_rp_SR_JobStatus_JobStatus_BsConst_Lookup_Curve_HotSpot_Coef_Y: accessed-variable=rp_SR_JobStatus.JobStatus_BsConst_Lookup_Curve_HotSpot_Coef_Y
              DRA_rp_SR_JobStatus_JobStatus_BsConst_Lookup_Curve_HotSpot_Coef_Y_SafeCopy1: accessed-variable=rp_SR_JobStatus.JobStatus_BsConst_Lookup_Curve_HotSpot_Coef_Y_SafeCopy1
              DRA_rp_SR_JobStatus_JobStatus_BsConst_Lookup_Curve_HotSpot_Coef_Y_SafeCopy2: accessed-variable=rp_SR_JobStatus.JobStatus_BsConst_Lookup_Curve_HotSpot_Coef_Y_SafeCopy2
              DRA_rp_SR_JobStatus_JobStatus_BsConst_PCB_Temperature_Sensor_Conv: accessed-variable=rp_SR_JobStatus.JobStatus_BsConst_PCB_Temperature_Sensor_Conv
              DRA_rp_SR_JobStatus_JobStatus_BsConst_PCB_Temperature_Sensor_Conv_SafeCopy1: accessed-variable=rp_SR_JobStatus.JobStatus_BsConst_PCB_Temperature_Sensor_Conv_SafeCopy1
              DRA_rp_SR_JobStatus_JobStatus_BsConst_PCB_Temperature_Sensor_Conv_SafeCopy2: accessed-variable=rp_SR_JobStatus.JobStatus_BsConst_PCB_Temperature_Sensor_Conv_SafeCopy2
              DRA_rp_SR_JobStatus_JobStatus_BsConst_PWM_boost_bypass_duty: accessed-variable=rp_SR_JobStatus.JobStatus_BsConst_PWM_boost_bypass_duty
              DRA_rp_SR_JobStatus_JobStatus_BsConst_PWM_boost_bypass_duty_SafeCopy1: accessed-variable=rp_SR_JobStatus.JobStatus_BsConst_PWM_boost_bypass_duty_SafeCopy1
              DRA_rp_SR_JobStatus_JobStatus_BsConst_PWM_boost_bypass_duty_SafeCopy2: accessed-variable=rp_SR_JobStatus.JobStatus_BsConst_PWM_boost_bypass_duty_SafeCopy2
              DRA_rp_SR_JobStatus_JobStatus_BsConst_Temp_Threshold_Hysteresis_Derating: accessed-variable=rp_SR_JobStatus.JobStatus_BsConst_Temp_Threshold_Hysteresis_Derating
              DRA_rp_SR_JobStatus_JobStatus_BsConst_Temp_Threshold_Hysteresis_Derating_SafeCopy1: accessed-variable=rp_SR_JobStatus.JobStatus_BsConst_Temp_Threshold_Hysteresis_Derating_SafeCopy1
              DRA_rp_SR_JobStatus_JobStatus_BsConst_Temp_Threshold_Hysteresis_Derating_SafeCopy2: accessed-variable=rp_SR_JobStatus.JobStatus_BsConst_Temp_Threshold_Hysteresis_Derating_SafeCopy2
              DRA_rp_SR_JobStatus_JobStatus_BsConst_Temperature_Sensor_Conv: accessed-variable=rp_SR_JobStatus.JobStatus_BsConst_Temperature_Sensor_Conv
              DRA_rp_SR_JobStatus_JobStatus_BsConst_Temperature_Sensor_Conv_SafeCopy1: accessed-variable=rp_SR_JobStatus.JobStatus_BsConst_Temperature_Sensor_Conv_SafeCopy1
              DRA_rp_SR_JobStatus_JobStatus_BsConst_Temperature_Sensor_Conv_SafeCopy2: accessed-variable=rp_SR_JobStatus.JobStatus_BsConst_Temperature_Sensor_Conv_SafeCopy2
              DRP_rSR_DiagResponse_DiagResponseData: accessed-variable=rSR_DiagResponse.DiagResponseData
          data-send-points:
            4 x access:
              DWA_pp_SR_SleepReq_SleepReqData: accessed-variable=pp_SR_SleepReq.SleepReqData
              DSP_pSR_DiagDIDRequest_DiagDIDRequestData: accessed-variable=pSR_DiagDIDRequest.DiagDIDRequestData
              DSP_pSR_DiagIOCtrlRequest_DiagIOCtrlRequestData: accessed-variable=pSR_DiagIOCtrlRequest.DiagIOCtrlRequestData
              DSP_pSR_DiagRoutineRequest_DiagRoutineRequestData: accessed-variable=pSR_DiagRoutineRequest.DiagRoutineRequestData
          200 x sync call:
            OA_rpIoHwAb_ADC_GetAsyncRawAdc: operation=rpIoHwAb_ADC.GetAsyncRawAdc
            OA_rpIoHwAb_ADC_GetSyncRawAdc: operation=rpIoHwAb_ADC.GetSyncRawAdc
            OA_rpIoHwAb_ADC_GetProcessedAdc: operation=rpIoHwAb_ADC.GetProcessedAdc
            OA_rpIoHwAb_DOut_SetOutputGroup: operation=rpIoHwAb_DOut.SetOutputGroup
            OA_rpIoHwAb_DOut_SetOutputPin: operation=rpIoHwAb_DOut.SetOutputPin
            OA_rpIoHwAb_Din_GetAsyncRawInput: operation=rpIoHwAb_Din.GetAsyncRawInput
            OA_rpIoHwAb_Din_GetProcessedInput: operation=rpIoHwAb_Din.GetProcessedInput
            OA_rpIoHwAb_Din_GetSyncRawInput: operation=rpIoHwAb_Din.GetSyncRawInput
            OA_rpIoHwAb_Din_GetInputGroup: operation=rpIoHwAb_Din.GetInputGroup
            OA_rpIoHwAb_PWM_PwmSetDuty: operation=rpIoHwAb_PWM.PwmSetDuty
            OA_rpIoHwAb_PWM_PwmSetDutyAndPeriod: operation=rpIoHwAb_PWM.PwmSetDutyAndPeriod
            OA_rpIoHwAb_PWM_PwmSetIdeal: operation=rpIoHwAb_PWM.PwmSetIdeal
            OA_rp_CS_MemAbsGet_Get_BsShare_SwUpdReflash_Element: operation=rp_CS_MemAbsGet.Get_BsShare_SwUpdReflash_Element
            OA_rp_CS_MemAbsGet_Get_BsShare_SwUpdFotaMode_Element: operation=rp_CS_MemAbsGet.Get_BsShare_SwUpdFotaMode_Element
            OA_rp_CS_MemAbsGet_Get_BsShare_SwUpdFotaFinPrint_Element: operation=rp_CS_MemAbsGet.Get_BsShare_SwUpdFotaFinPrint_Element
            OA_rp_CS_MemAbsGet_Get_BsShare_SwUpdFotaStatus_Element: operation=rp_CS_MemAbsGet.Get_BsShare_SwUpdFotaStatus_Element
            OA_rp_CS_MemAbsGet_Get_BsShare_SwUpdFotadecrypt_Element: operation=rp_CS_MemAbsGet.Get_BsShare_SwUpdFotadecrypt_Element
            OA_rp_CS_MemAbsGet_Get_BsShare_EcuPartNumber_Element: operation=rp_CS_MemAbsGet.Get_BsShare_EcuPartNumber_Element
            OA_rp_CS_MemAbsGet_Get_BsShare_VisMeet_Element: operation=rp_CS_MemAbsGet.Get_BsShare_VisMeet_Element
            OA_rp_CS_MemAbsGet_Get_BsShare_VehicleConfig_Element: operation=rp_CS_MemAbsGet.Get_BsShare_VehicleConfig_Element
            OA_rp_CS_MemAbsGet_Get_BsConst_SpeedoGauge_Element: operation=rp_CS_MemAbsGet.Get_BsConst_SpeedoGauge_Element
            OA_rp_CS_MemAbsGet_Get_BsConst_TachoGauge_Element: operation=rp_CS_MemAbsGet.Get_BsConst_TachoGauge_Element
            OA_rp_CS_MemAbsGet_Get_BsConst_FuelGauge_Element: operation=rp_CS_MemAbsGet.Get_BsConst_FuelGauge_Element
            OA_rp_CS_MemAbsGet_Get_BsConst_TempGauge_Element: operation=rp_CS_MemAbsGet.Get_BsConst_TempGauge_Element
            OA_rp_CS_MemAbsGet_Get_BsConst_PowerGauge_Element: operation=rp_CS_MemAbsGet.Get_BsConst_PowerGauge_Element
            OA_rp_CS_MemAbsGet_Get_BsConst_OilGauge_Element: operation=rp_CS_MemAbsGet.Get_BsConst_OilGauge_Element
            OA_rp_CS_MemAbsGet_Get_BsConst_TripComputer_Element: operation=rp_CS_MemAbsGet.Get_BsConst_TripComputer_Element
            OA_rp_CS_MemAbsGet_Get_BsConst_Audio_Element: operation=rp_CS_MemAbsGet.Get_BsConst_Audio_Element
            OA_rp_CS_MemAbsGet_Get_BsConst_Warning_Element: operation=rp_CS_MemAbsGet.Get_BsConst_Warning_Element
            OA_rp_CS_MemAbsGet_Get_BsConst_RealTimeClock_Element: operation=rp_CS_MemAbsGet.Get_BsConst_RealTimeClock_Element
            OA_rp_CS_MemAbsGet_Get_BsConst_Communication_Element: operation=rp_CS_MemAbsGet.Get_BsConst_Communication_Element
            OA_rp_CS_MemAbsGet_Get_BsConst_Power_Element: operation=rp_CS_MemAbsGet.Get_BsConst_Power_Element
            OA_rp_CS_MemAbsGet_Get_BsConst_ServiceReminder_Element: operation=rp_CS_MemAbsGet.Get_BsConst_ServiceReminder_Element
            OA_rp_CS_MemAbsGet_Get_BsConst_EngOffTimer_Element: operation=rp_CS_MemAbsGet.Get_BsConst_EngOffTimer_Element
            OA_rp_CS_MemAbsGet_Get_BsCys_Certicificate_Element: operation=rp_CS_MemAbsGet.Get_BsCys_Certicificate_Element
            OA_rp_CS_MemAbsGet_Get_RefCys_Certicificate_Element: operation=rp_CS_MemAbsGet.Get_RefCys_Certicificate_Element
            OA_rp_CS_MemAbsGet_Get_RefCys_Certicificate1_Element: operation=rp_CS_MemAbsGet.Get_RefCys_Certicificate1_Element
            OA_rp_CS_MemAbsGet_Get_BsRt_Odometer_Element: operation=rp_CS_MemAbsGet.Get_BsRt_Odometer_Element
            OA_rp_CS_MemAbsGet_Get_BsRt_SpeedoGauge_Element: operation=rp_CS_MemAbsGet.Get_BsRt_SpeedoGauge_Element
            OA_rp_CS_MemAbsGet_Get_BsRt_TachoGauge_Element: operation=rp_CS_MemAbsGet.Get_BsRt_TachoGauge_Element
            OA_rp_CS_MemAbsGet_Get_BsRt_FuelGauge_Element: operation=rp_CS_MemAbsGet.Get_BsRt_FuelGauge_Element
            OA_rp_CS_MemAbsGet_Get_BsRt_TempGauge_Element: operation=rp_CS_MemAbsGet.Get_BsRt_TempGauge_Element
            OA_rp_CS_MemAbsGet_Get_BsRt_PowerGauge_Element: operation=rp_CS_MemAbsGet.Get_BsRt_PowerGauge_Element
            OA_rp_CS_MemAbsGet_Get_BsRt_OilGauge_Element: operation=rp_CS_MemAbsGet.Get_BsRt_OilGauge_Element
            OA_rp_CS_MemAbsGet_Get_BsRt_TripComputer_Element: operation=rp_CS_MemAbsGet.Get_BsRt_TripComputer_Element
            OA_rp_CS_MemAbsGet_Get_BsRt_Warning_Element: operation=rp_CS_MemAbsGet.Get_BsRt_Warning_Element
            OA_rp_CS_MemAbsGet_Get_BsRt_RealTimeClock_Element: operation=rp_CS_MemAbsGet.Get_BsRt_RealTimeClock_Element
            OA_rp_CS_MemAbsGet_Get_BsRt_Personalization_Element: operation=rp_CS_MemAbsGet.Get_BsRt_Personalization_Element
            OA_rp_CS_MemAbsGet_Get_BsRt_Illumination_Element: operation=rp_CS_MemAbsGet.Get_BsRt_Illumination_Element
            OA_rp_CS_MemAbsGet_Get_BsRt_CusDlt_Element: operation=rp_CS_MemAbsGet.Get_BsRt_CusDlt_Element
            OA_rp_CS_MemAbsGet_Get_BsReten_Odometer_Element: operation=rp_CS_MemAbsGet.Get_BsReten_Odometer_Element
            OA_rp_CS_MemAbsGet_Get_BsReten_Gauges_Element: operation=rp_CS_MemAbsGet.Get_BsReten_Gauges_Element
            OA_rp_CS_MemAbsGet_Get_BsReten_Tripcomputer_Element: operation=rp_CS_MemAbsGet.Get_BsReten_Tripcomputer_Element
            OA_rp_CS_MemAbsGet_Get_BsReten_Illumination_Element: operation=rp_CS_MemAbsGet.Get_BsReten_Illumination_Element
            OA_rp_CS_MemAbsGet_Get_BsReten_Audio_Element: operation=rp_CS_MemAbsGet.Get_BsReten_Audio_Element
            OA_rp_CS_MemAbsGet_Get_BsReten_Warning_Element: operation=rp_CS_MemAbsGet.Get_BsReten_Warning_Element
            OA_rp_CS_MemAbsGet_Get_BsReten_RealTimeClock_Element: operation=rp_CS_MemAbsGet.Get_BsReten_RealTimeClock_Element
            OA_rp_CS_MemAbsGet_Get_BsReten_Communication_Element: operation=rp_CS_MemAbsGet.Get_BsReten_Communication_Element
            OA_rp_CS_MemAbsGet_Get_BsReten_Personalization_Element: operation=rp_CS_MemAbsGet.Get_BsReten_Personalization_Element
            OA_rp_CS_MemAbsGet_Get_BsReten_Power_Element: operation=rp_CS_MemAbsGet.Get_BsReten_Power_Element
            OA_rp_CS_MemAbsGet_Get_BsReten_Display_Element: operation=rp_CS_MemAbsGet.Get_BsReten_Display_Element
            OA_rp_CS_MemAbsGet_Get_BsDiag_ErrorRecord_Element: operation=rp_CS_MemAbsGet.Get_BsDiag_ErrorRecord_Element
            OA_rp_CS_MemAbsGet_Get_BsDiag_Dtc_Element: operation=rp_CS_MemAbsGet.Get_BsDiag_Dtc_Element
            OA_rp_CS_MemAbsSet_Set_BsShare_SwUpdReflash_Element: operation=rp_CS_MemAbsSet.Set_BsShare_SwUpdReflash_Element
            OA_rp_CS_MemAbsSet_Set_BsShare_SwUpdFotaMode_Element: operation=rp_CS_MemAbsSet.Set_BsShare_SwUpdFotaMode_Element
            OA_rp_CS_MemAbsSet_Set_BsShare_SwUpdFotaFinPrint_Element: operation=rp_CS_MemAbsSet.Set_BsShare_SwUpdFotaFinPrint_Element
            OA_rp_CS_MemAbsSet_Set_BsShare_SwUpdFotaStatus_Element: operation=rp_CS_MemAbsSet.Set_BsShare_SwUpdFotaStatus_Element
            OA_rp_CS_MemAbsSet_Set_BsShare_SwUpdFotadecrypt_Element: operation=rp_CS_MemAbsSet.Set_BsShare_SwUpdFotadecrypt_Element
            OA_rp_CS_MemAbsSet_Set_BsShare_EcuPartNumber_Element: operation=rp_CS_MemAbsSet.Set_BsShare_EcuPartNumber_Element
            OA_rp_CS_MemAbsSet_Set_BsShare_VisMeet_Element: operation=rp_CS_MemAbsSet.Set_BsShare_VisMeet_Element
            OA_rp_CS_MemAbsSet_Set_BsShare_VehicleConfig_Element: operation=rp_CS_MemAbsSet.Set_BsShare_VehicleConfig_Element
            OA_rp_CS_MemAbsSet_Set_BsConst_SpeedoGauge_Element: operation=rp_CS_MemAbsSet.Set_BsConst_SpeedoGauge_Element
            OA_rp_CS_MemAbsSet_Set_BsConst_TachoGauge_Element: operation=rp_CS_MemAbsSet.Set_BsConst_TachoGauge_Element
            OA_rp_CS_MemAbsSet_Set_BsConst_FuelGauge_Element: operation=rp_CS_MemAbsSet.Set_BsConst_FuelGauge_Element
            OA_rp_CS_MemAbsSet_Set_BsConst_TempGauge_Element: operation=rp_CS_MemAbsSet.Set_BsConst_TempGauge_Element
            OA_rp_CS_MemAbsSet_Set_BsConst_PowerGauge_Element: operation=rp_CS_MemAbsSet.Set_BsConst_PowerGauge_Element
            OA_rp_CS_MemAbsSet_Set_BsConst_OilGauge_Element: operation=rp_CS_MemAbsSet.Set_BsConst_OilGauge_Element
            OA_rp_CS_MemAbsSet_Set_BsConst_TripComputer_Element: operation=rp_CS_MemAbsSet.Set_BsConst_TripComputer_Element
            OA_rp_CS_MemAbsSet_Set_BsConst_Audio_Element: operation=rp_CS_MemAbsSet.Set_BsConst_Audio_Element
            OA_rp_CS_MemAbsSet_Set_BsConst_Warning_Element: operation=rp_CS_MemAbsSet.Set_BsConst_Warning_Element
            OA_rp_CS_MemAbsSet_Set_BsConst_RealTimeClock_Element: operation=rp_CS_MemAbsSet.Set_BsConst_RealTimeClock_Element
            OA_rp_CS_MemAbsSet_Set_BsConst_Communication_Element: operation=rp_CS_MemAbsSet.Set_BsConst_Communication_Element
            OA_rp_CS_MemAbsSet_Set_BsConst_Power_Element: operation=rp_CS_MemAbsSet.Set_BsConst_Power_Element
            OA_rp_CS_MemAbsSet_Set_BsConst_ServiceReminder_Element: operation=rp_CS_MemAbsSet.Set_BsConst_ServiceReminder_Element
            OA_rp_CS_MemAbsSet_Set_BsConst_EngOffTimer_Element: operation=rp_CS_MemAbsSet.Set_BsConst_EngOffTimer_Element
            OA_rp_CS_MemAbsSet_Set_BsCys_Certicificate_Element: operation=rp_CS_MemAbsSet.Set_BsCys_Certicificate_Element
            OA_rp_CS_MemAbsSet_Set_RefCys_Certicificate_Element: operation=rp_CS_MemAbsSet.Set_RefCys_Certicificate_Element
            OA_rp_CS_MemAbsSet_Set_RefCys_Certicificate1_Element: operation=rp_CS_MemAbsSet.Set_RefCys_Certicificate1_Element
            OA_rp_CS_MemAbsSet_Set_BsRt_Odometer_Element: operation=rp_CS_MemAbsSet.Set_BsRt_Odometer_Element
            OA_rp_CS_MemAbsSet_Set_BsRt_SpeedoGauge_Element: operation=rp_CS_MemAbsSet.Set_BsRt_SpeedoGauge_Element
            OA_rp_CS_MemAbsSet_Set_BsRt_TachoGauge_Element: operation=rp_CS_MemAbsSet.Set_BsRt_TachoGauge_Element
            OA_rp_CS_MemAbsSet_Set_BsRt_FuelGauge_Element: operation=rp_CS_MemAbsSet.Set_BsRt_FuelGauge_Element
            OA_rp_CS_MemAbsSet_Set_BsRt_TempGauge_Element: operation=rp_CS_MemAbsSet.Set_BsRt_TempGauge_Element
            OA_rp_CS_MemAbsSet_Set_BsRt_PowerGauge_Element: operation=rp_CS_MemAbsSet.Set_BsRt_PowerGauge_Element
            OA_rp_CS_MemAbsSet_Set_BsRt_OilGauge_Element: operation=rp_CS_MemAbsSet.Set_BsRt_OilGauge_Element
            OA_rp_CS_MemAbsSet_Set_BsRt_TripComputer_Element: operation=rp_CS_MemAbsSet.Set_BsRt_TripComputer_Element
            OA_rp_CS_MemAbsSet_Set_BsRt_Warning_Element: operation=rp_CS_MemAbsSet.Set_BsRt_Warning_Element
            OA_rp_CS_MemAbsSet_Set_BsRt_RealTimeClock_Element: operation=rp_CS_MemAbsSet.Set_BsRt_RealTimeClock_Element
            OA_rp_CS_MemAbsSet_Set_BsRt_Personalization_Element: operation=rp_CS_MemAbsSet.Set_BsRt_Personalization_Element
            OA_rp_CS_MemAbsSet_Set_BsRt_Illumination_Element: operation=rp_CS_MemAbsSet.Set_BsRt_Illumination_Element
            OA_rp_CS_MemAbsSet_Set_BsRt_CusDlt_Element: operation=rp_CS_MemAbsSet.Set_BsRt_CusDlt_Element
            OA_rp_CS_MemAbsSet_Set_BsReten_Odometer_Element: operation=rp_CS_MemAbsSet.Set_BsReten_Odometer_Element
            OA_rp_CS_MemAbsSet_Set_BsReten_Gauges_Element: operation=rp_CS_MemAbsSet.Set_BsReten_Gauges_Element
            OA_rp_CS_MemAbsSet_Set_BsReten_Tripcomputer_Element: operation=rp_CS_MemAbsSet.Set_BsReten_Tripcomputer_Element
            OA_rp_CS_MemAbsSet_Set_BsReten_Illumination_Element: operation=rp_CS_MemAbsSet.Set_BsReten_Illumination_Element
            OA_rp_CS_MemAbsSet_Set_BsReten_Audio_Element: operation=rp_CS_MemAbsSet.Set_BsReten_Audio_Element
            OA_rp_CS_MemAbsSet_Set_BsReten_Warning_Element: operation=rp_CS_MemAbsSet.Set_BsReten_Warning_Element
            OA_rp_CS_MemAbsSet_Set_BsReten_RealTimeClock_Element: operation=rp_CS_MemAbsSet.Set_BsReten_RealTimeClock_Element
            OA_rp_CS_MemAbsSet_Set_BsReten_Communication_Element: operation=rp_CS_MemAbsSet.Set_BsReten_Communication_Element
            OA_rp_CS_MemAbsSet_Set_BsReten_Personalization_Element: operation=rp_CS_MemAbsSet.Set_BsReten_Personalization_Element
            OA_rp_CS_MemAbsSet_Set_BsReten_Power_Element: operation=rp_CS_MemAbsSet.Set_BsReten_Power_Element
            OA_rp_CS_MemAbsSet_Set_BsReten_Display_Element: operation=rp_CS_MemAbsSet.Set_BsReten_Display_Element
            OA_rp_CS_MemAbsSet_Set_BsDiag_ErrorRecord_Element: operation=rp_CS_MemAbsSet.Set_BsDiag_ErrorRecord_Element
            OA_rp_CS_MemAbsSet_Set_BsDiag_Dtc_Element: operation=rp_CS_MemAbsSet.Set_BsDiag_Dtc_Element
            OA_rp_CS_MemAbsGet_Get_BsShare_VisMeet_EOLEntry_Element: operation=rp_CS_MemAbsGet.Get_BsShare_VisMeet_EOLEntry_Element
            OA_rp_CS_MemAbsSet_Set_BsShare_VisMeet_EOLEntry_Element: operation=rp_CS_MemAbsSet.Set_BsShare_VisMeet_EOLEntry_Element
            OA_rp_CS_MemAbsGet_Get_BsShare_VisteonPartNumber: operation=rp_CS_MemAbsGet.Get_BsShare_VisteonPartNumber
            OA_rp_CS_MemAbsGet_Get_BsShare_VisteonPCBPartNumber: operation=rp_CS_MemAbsGet.Get_BsShare_VisteonPCBPartNumber
            OA_rp_CS_MemAbsGet_Get_BsShare_ProductSerialNumber: operation=rp_CS_MemAbsGet.Get_BsShare_ProductSerialNumber
            OA_rp_CS_MemAbsGet_Get_BsShare_PCBSerialNumber: operation=rp_CS_MemAbsGet.Get_BsShare_PCBSerialNumber
            OA_rp_CS_MemAbsGet_Get_BsShare_SMTManufacturingDate: operation=rp_CS_MemAbsGet.Get_BsShare_SMTManufacturingDate
            OA_rp_CS_MemAbsGet_Get_BsShare_AssemblyManufacturingDate: operation=rp_CS_MemAbsGet.Get_BsShare_AssemblyManufacturingDate
            OA_rp_CS_MemAbsGet_Get_BsShare_SMTPlantNumber: operation=rp_CS_MemAbsGet.Get_BsShare_SMTPlantNumber
            OA_rp_CS_MemAbsGet_Get_BsShare_AssemblyPlantNumber: operation=rp_CS_MemAbsGet.Get_BsShare_AssemblyPlantNumber
            OA_rp_CS_MemAbsGet_Get_BsShare_HWModification: operation=rp_CS_MemAbsGet.Get_BsShare_HWModification
            OA_rp_CS_MemAbsSet_Set_BsShare_VisteonPartNumber: operation=rp_CS_MemAbsSet.Set_BsShare_VisteonPartNumber
            OA_rp_CS_MemAbsSet_Set_BsShare_VisteonPCBPartNumber: operation=rp_CS_MemAbsSet.Set_BsShare_VisteonPCBPartNumber
            OA_rp_CS_MemAbsSet_Set_BsShare_ProductSerialNumber: operation=rp_CS_MemAbsSet.Set_BsShare_ProductSerialNumber
            OA_rp_CS_MemAbsSet_Set_BsShare_PCBSerialNumber: operation=rp_CS_MemAbsSet.Set_BsShare_PCBSerialNumber
            OA_rp_CS_MemAbsSet_Set_BsShare_SMTManufacturingDate: operation=rp_CS_MemAbsSet.Set_BsShare_SMTManufacturingDate
            OA_rp_CS_MemAbsSet_Set_BsShare_AssemblyManufacturingDate: operation=rp_CS_MemAbsSet.Set_BsShare_AssemblyManufacturingDate
            OA_rp_CS_MemAbsSet_Set_BsShare_SMTPlantNumber: operation=rp_CS_MemAbsSet.Set_BsShare_SMTPlantNumber
            OA_rp_CS_MemAbsSet_Set_BsShare_AssemblyPlantNumber: operation=rp_CS_MemAbsSet.Set_BsShare_AssemblyPlantNumber
            OA_rp_CS_MemAbsSet_Set_BsShare_HWModification: operation=rp_CS_MemAbsSet.Set_BsShare_HWModification
            OA_rp_CS_MemAbsGet_Get_BsConst_Compensation_Line_Slope_m: operation=rp_CS_MemAbsGet.Get_BsConst_Compensation_Line_Slope_m
            OA_rp_CS_MemAbsGet_Get_BsConst_Compensation_Line_Shift_b: operation=rp_CS_MemAbsGet.Get_BsConst_Compensation_Line_Shift_b
            OA_rp_CS_MemAbsGet_Get_BsConst_Lookup_Curve_HotSpot_Coef_X: operation=rp_CS_MemAbsGet.Get_BsConst_Lookup_Curve_HotSpot_Coef_X
            OA_rp_CS_MemAbsGet_Get_BsConst_Lookup_Curve_HotSpot_Coef_Y: operation=rp_CS_MemAbsGet.Get_BsConst_Lookup_Curve_HotSpot_Coef_Y
            OA_rp_CS_MemAbsGet_Get_BsConst_Temp_Threshold_Hysteresis_Derating: operation=rp_CS_MemAbsGet.Get_BsConst_Temp_Threshold_Hysteresis_Derating
            OA_rp_CS_MemAbsGet_Get_BsConst_Derating_Backlight_Disable: operation=rp_CS_MemAbsGet.Get_BsConst_Derating_Backlight_Disable
            OA_rp_CS_MemAbsGet_Get_BsConst_Temperature_Sensor_Conv: operation=rp_CS_MemAbsGet.Get_BsConst_Temperature_Sensor_Conv
            OA_rp_CS_MemAbsGet_Get_BsConst_PCB_Temperature_Sensor_Conv: operation=rp_CS_MemAbsGet.Get_BsConst_PCB_Temperature_Sensor_Conv
            OA_rp_CS_MemAbsGet_Get_BsConst_Display_Illum_Max_Level: operation=rp_CS_MemAbsGet.Get_BsConst_Display_Illum_Max_Level
            OA_rp_CS_MemAbsGet_Get_BsConst_PWM_boost_bypass_duty: operation=rp_CS_MemAbsGet.Get_BsConst_PWM_boost_bypass_duty
            OA_rp_CS_MemAbsGet_Get_BsConst_BsConst_Illumination_ReservedByte: operation=rp_CS_MemAbsGet.Get_BsConst_BsConst_Illumination_ReservedByte
            OA_rp_CS_MemAbsGet_Get_BsConst_Compensation_Line_Slope_m_SafeCopy1: operation=rp_CS_MemAbsGet.Get_BsConst_Compensation_Line_Slope_m_SafeCopy1
            OA_rp_CS_MemAbsGet_Get_BsConst_Compensation_Line_Shift_b_SafeCopy1: operation=rp_CS_MemAbsGet.Get_BsConst_Compensation_Line_Shift_b_SafeCopy1
            OA_rp_CS_MemAbsGet_Get_BsConst_Lookup_Curve_HotSpot_Coef_X_SafeCopy1: operation=rp_CS_MemAbsGet.Get_BsConst_Lookup_Curve_HotSpot_Coef_X_SafeCopy1
            OA_rp_CS_MemAbsGet_Get_BsConst_Lookup_Curve_HotSpot_Coef_Y_SafeCopy1: operation=rp_CS_MemAbsGet.Get_BsConst_Lookup_Curve_HotSpot_Coef_Y_SafeCopy1
            OA_rp_CS_MemAbsGet_Get_BsConst_Temp_Threshold_Hysteresis_Derating_SafeCopy1: operation=rp_CS_MemAbsGet.Get_BsConst_Temp_Threshold_Hysteresis_Derating_SafeCopy1
            OA_rp_CS_MemAbsGet_Get_BsConst_Derating_Backlight_Disable_SafeCopy1: operation=rp_CS_MemAbsGet.Get_BsConst_Derating_Backlight_Disable_SafeCopy1
            OA_rp_CS_MemAbsGet_Get_BsConst_Temperature_Sensor_Conv_SafeCopy1: operation=rp_CS_MemAbsGet.Get_BsConst_Temperature_Sensor_Conv_SafeCopy1
            OA_rp_CS_MemAbsGet_Get_BsConst_PCB_Temperature_Sensor_Conv_SafeCopy1: operation=rp_CS_MemAbsGet.Get_BsConst_PCB_Temperature_Sensor_Conv_SafeCopy1
            OA_rp_CS_MemAbsGet_Get_BsConst_Display_Illum_Max_Level_SafeCopy1: operation=rp_CS_MemAbsGet.Get_BsConst_Display_Illum_Max_Level_SafeCopy1
            OA_rp_CS_MemAbsGet_Get_BsConst_PWM_boost_bypass_duty_SafeCopy1: operation=rp_CS_MemAbsGet.Get_BsConst_PWM_boost_bypass_duty_SafeCopy1
            OA_rp_CS_MemAbsGet_Get_BsConst_BsConst_Illumination_ReservedByte_SafeCopy1: operation=rp_CS_MemAbsGet.Get_BsConst_BsConst_Illumination_ReservedByte_SafeCopy1
            OA_rp_CS_MemAbsGet_Get_BsConst_Compensation_Line_Slope_m_SafeCopy2: operation=rp_CS_MemAbsGet.Get_BsConst_Compensation_Line_Slope_m_SafeCopy2
            OA_rp_CS_MemAbsGet_Get_BsConst_Compensation_Line_Shift_b_SafeCopy2: operation=rp_CS_MemAbsGet.Get_BsConst_Compensation_Line_Shift_b_SafeCopy2
            OA_rp_CS_MemAbsGet_Get_BsConst_Lookup_Curve_HotSpot_Coef_X_SafeCopy2: operation=rp_CS_MemAbsGet.Get_BsConst_Lookup_Curve_HotSpot_Coef_X_SafeCopy2
            OA_rp_CS_MemAbsGet_Get_BsConst_Lookup_Curve_HotSpot_Coef_Y_SafeCopy2: operation=rp_CS_MemAbsGet.Get_BsConst_Lookup_Curve_HotSpot_Coef_Y_SafeCopy2
            OA_rp_CS_MemAbsGet_Get_BsConst_Temp_Threshold_Hysteresis_Derating_SafeCopy2: operation=rp_CS_MemAbsGet.Get_BsConst_Temp_Threshold_Hysteresis_Derating_SafeCopy2
            OA_rp_CS_MemAbsGet_Get_BsConst_Derating_Backlight_Disable_SafeCopy2: operation=rp_CS_MemAbsGet.Get_BsConst_Derating_Backlight_Disable_SafeCopy2
            OA_rp_CS_MemAbsGet_Get_BsConst_Temperature_Sensor_Conv_SafeCopy2: operation=rp_CS_MemAbsGet.Get_BsConst_Temperature_Sensor_Conv_SafeCopy2
            OA_rp_CS_MemAbsGet_Get_BsConst_PCB_Temperature_Sensor_Conv_SafeCopy2: operation=rp_CS_MemAbsGet.Get_BsConst_PCB_Temperature_Sensor_Conv_SafeCopy2
            OA_rp_CS_MemAbsGet_Get_BsConst_Display_Illum_Max_Level_SafeCopy2: operation=rp_CS_MemAbsGet.Get_BsConst_Display_Illum_Max_Level_SafeCopy2
            OA_rp_CS_MemAbsGet_Get_BsConst_PWM_boost_bypass_duty_SafeCopy2: operation=rp_CS_MemAbsGet.Get_BsConst_PWM_boost_bypass_duty_SafeCopy2
            OA_rp_CS_MemAbsGet_Get_BsConst_BsConst_Illumination_ReservedByte_SafeCopy2: operation=rp_CS_MemAbsGet.Get_BsConst_BsConst_Illumination_ReservedByte_SafeCopy2
            OA_rp_CS_MemAbsSet_Set_BsConst_Compensation_Line_Slope_m: operation=rp_CS_MemAbsSet.Set_BsConst_Compensation_Line_Slope_m
            OA_rp_CS_MemAbsSet_Set_BsConst_Compensation_Line_Shift_b: operation=rp_CS_MemAbsSet.Set_BsConst_Compensation_Line_Shift_b
            OA_rp_CS_MemAbsSet_Set_BsConst_Lookup_Curve_HotSpot_Coef_X: operation=rp_CS_MemAbsSet.Set_BsConst_Lookup_Curve_HotSpot_Coef_X
            OA_rp_CS_MemAbsSet_Set_BsConst_Lookup_Curve_HotSpot_Coef_Y: operation=rp_CS_MemAbsSet.Set_BsConst_Lookup_Curve_HotSpot_Coef_Y
            OA_rp_CS_MemAbsSet_Set_BsConst_Temp_Threshold_Hysteresis_Derating: operation=rp_CS_MemAbsSet.Set_BsConst_Temp_Threshold_Hysteresis_Derating
            OA_rp_CS_MemAbsSet_Set_BsConst_Derating_Backlight_Disable: operation=rp_CS_MemAbsSet.Set_BsConst_Derating_Backlight_Disable
            OA_rp_CS_MemAbsSet_Set_BsConst_Temperature_Sensor_Conv: operation=rp_CS_MemAbsSet.Set_BsConst_Temperature_Sensor_Conv
            OA_rp_CS_MemAbsSet_Set_BsConst_PCB_Temperature_Sensor_Conv: operation=rp_CS_MemAbsSet.Set_BsConst_PCB_Temperature_Sensor_Conv
            OA_rp_CS_MemAbsSet_Set_BsConst_Display_Illum_Max_Level: operation=rp_CS_MemAbsSet.Set_BsConst_Display_Illum_Max_Level
            OA_rp_CS_MemAbsSet_Set_BsConst_PWM_boost_bypass_duty: operation=rp_CS_MemAbsSet.Set_BsConst_PWM_boost_bypass_duty
            OA_rp_CS_MemAbsSet_Set_BsConst_BsConst_Illumination_ReservedByte: operation=rp_CS_MemAbsSet.Set_BsConst_BsConst_Illumination_ReservedByte
            OA_rp_CS_MemAbsSet_Set_BsConst_Compensation_Line_Slope_m_SafeCopy1: operation=rp_CS_MemAbsSet.Set_BsConst_Compensation_Line_Slope_m_SafeCopy1
            OA_rp_CS_MemAbsSet_Set_BsConst_Compensation_Line_Shift_b_SafeCopy1: operation=rp_CS_MemAbsSet.Set_BsConst_Compensation_Line_Shift_b_SafeCopy1
            OA_rp_CS_MemAbsSet_Set_BsConst_Lookup_Curve_HotSpot_Coef_X_SafeCopy1: operation=rp_CS_MemAbsSet.Set_BsConst_Lookup_Curve_HotSpot_Coef_X_SafeCopy1
            OA_rp_CS_MemAbsSet_Set_BsConst_Lookup_Curve_HotSpot_Coef_Y_SafeCopy1: operation=rp_CS_MemAbsSet.Set_BsConst_Lookup_Curve_HotSpot_Coef_Y_SafeCopy1
            OA_rp_CS_MemAbsSet_Set_BsConst_Temp_Threshold_Hysteresis_Derating_SafeCopy1: operation=rp_CS_MemAbsSet.Set_BsConst_Temp_Threshold_Hysteresis_Derating_SafeCopy1
            OA_rp_CS_MemAbsSet_Set_BsConst_Derating_Backlight_Disable_SafeCopy1: operation=rp_CS_MemAbsSet.Set_BsConst_Derating_Backlight_Disable_SafeCopy1
            OA_rp_CS_MemAbsSet_Set_BsConst_Temperature_Sensor_Conv_SafeCopy1: operation=rp_CS_MemAbsSet.Set_BsConst_Temperature_Sensor_Conv_SafeCopy1
            OA_rp_CS_MemAbsSet_Set_BsConst_PCB_Temperature_Sensor_Conv_SafeCopy1: operation=rp_CS_MemAbsSet.Set_BsConst_PCB_Temperature_Sensor_Conv_SafeCopy1
            OA_rp_CS_MemAbsSet_Set_BsConst_Display_Illum_Max_Level_SafeCopy1: operation=rp_CS_MemAbsSet.Set_BsConst_Display_Illum_Max_Level_SafeCopy1
            OA_rp_CS_MemAbsSet_Set_BsConst_PWM_boost_bypass_duty_SafeCopy1: operation=rp_CS_MemAbsSet.Set_BsConst_PWM_boost_bypass_duty_SafeCopy1
            OA_rp_CS_MemAbsSet_Set_BsConst_BsConst_Illumination_ReservedByte_SafeCopy1: operation=rp_CS_MemAbsSet.Set_BsConst_BsConst_Illumination_ReservedByte_SafeCopy1
            OA_rp_CS_MemAbsSet_Set_BsConst_Compensation_Line_Slope_m_SafeCopy2: operation=rp_CS_MemAbsSet.Set_BsConst_Compensation_Line_Slope_m_SafeCopy2
            OA_rp_CS_MemAbsSet_Set_BsConst_Compensation_Line_Shift_b_SafeCopy2: operation=rp_CS_MemAbsSet.Set_BsConst_Compensation_Line_Shift_b_SafeCopy2
            OA_rp_CS_MemAbsSet_Set_BsConst_Lookup_Curve_HotSpot_Coef_X_SafeCopy2: operation=rp_CS_MemAbsSet.Set_BsConst_Lookup_Curve_HotSpot_Coef_X_SafeCopy2
            OA_rp_CS_MemAbsSet_Set_BsConst_Lookup_Curve_HotSpot_Coef_Y_SafeCopy2: operation=rp_CS_MemAbsSet.Set_BsConst_Lookup_Curve_HotSpot_Coef_Y_SafeCopy2
            OA_rp_CS_MemAbsSet_Set_BsConst_Temp_Threshold_Hysteresis_Derating_SafeCopy2: operation=rp_CS_MemAbsSet.Set_BsConst_Temp_Threshold_Hysteresis_Derating_SafeCopy2
            OA_rp_CS_MemAbsSet_Set_BsConst_Derating_Backlight_Disable_SafeCopy2: operation=rp_CS_MemAbsSet.Set_BsConst_Derating_Backlight_Disable_SafeCopy2
            OA_rp_CS_MemAbsSet_Set_BsConst_Temperature_Sensor_Conv_SafeCopy2: operation=rp_CS_MemAbsSet.Set_BsConst_Temperature_Sensor_Conv_SafeCopy2
            OA_rp_CS_MemAbsSet_Set_BsConst_PCB_Temperature_Sensor_Conv_SafeCopy2: operation=rp_CS_MemAbsSet.Set_BsConst_PCB_Temperature_Sensor_Conv_SafeCopy2
            OA_rp_CS_MemAbsSet_Set_BsConst_Display_Illum_Max_Level_SafeCopy2: operation=rp_CS_MemAbsSet.Set_BsConst_Display_Illum_Max_Level_SafeCopy2
            OA_rp_CS_MemAbsSet_Set_BsConst_PWM_boost_bypass_duty_SafeCopy2: operation=rp_CS_MemAbsSet.Set_BsConst_PWM_boost_bypass_duty_SafeCopy2
            OA_rp_CS_MemAbsSet_Set_BsConst_BsConst_Illumination_ReservedByte_SafeCopy2: operation=rp_CS_MemAbsSet.Set_BsConst_BsConst_Illumination_ReservedByte_SafeCopy2
        CMeetCdd_Impl_OnCommand
        CMeetCdd_Meet_Mgrdiagcdd_Action
        CMeetCdd_RID_DiagAction
        CMeetCdd_Read_ManufModeStatus
        CMeetCdd_Write_Mfg_Flag
  swc implementation IMPL_CMeetCdd: behavior=IB_CMeetCdd
